VERSION "fleet-can-dataset generic_vehicle v0.1"

NS_ :

BS_:

BU_: ECM ABS APP BCM EPS

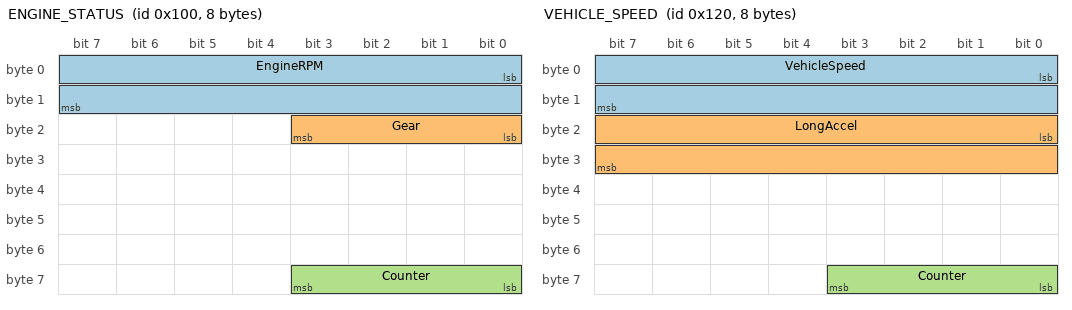
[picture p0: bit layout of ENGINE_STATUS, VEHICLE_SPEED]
BO_ 256 ENGINE_STATUS: 8 ECM
 SG_ EngineRPM : 0|16@1+ (0.25,0) [0|16383.75] "rpm" Vector__XXX
 SG_ Gear : 16|4@1+ (1,0) [0|15] "" Vector__XXX
 SG_ Counter : 56|4@1+ (1,0) [0|15] "" Vector__XXX

BO_ 288 VEHICLE_SPEED: 8 ABS
 SG_ VehicleSpeed : 0|16@1+ (0.01,0) [0|655.35] "km/h" Vector__XXX
 SG_ LongAccel : 16|16@1- (0.001,0) [-32.768|32.767] "m/s^2" Vector__XXX
 SG_ Counter : 56|4@1+ (1,0) [0|15] "" Vector__XXX

BO_ 336 ACCEL_PEDAL: 8 APP
 SG_ AccelPedalPos : 0|8@1+ (0.4,0) [0|100] "%" Vector__XXX
 SG_ Counter : 56|4@1+ (1,0) [0|15] "" Vector__XXX

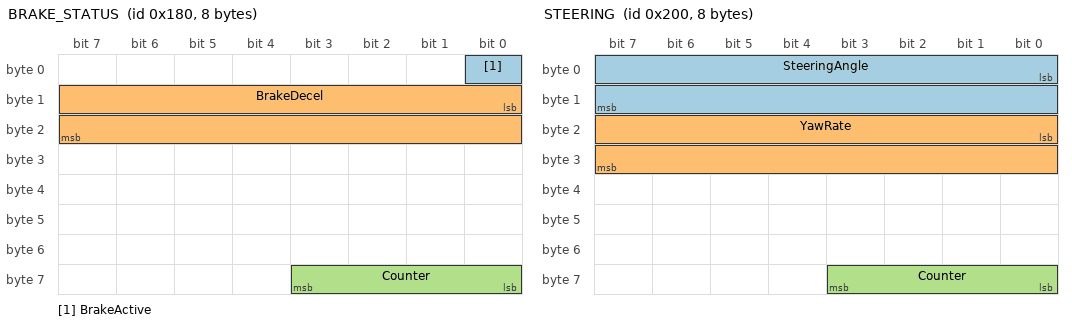
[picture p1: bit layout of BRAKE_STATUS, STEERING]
BO_ 384 BRAKE_STATUS: 8 BCM
 SG_ BrakeActive : 0|1@1+ (1,0) [0|1] "" Vector__XXX
 SG_ BrakeDecel : 8|16@1+ (0.001,0) [0|65.535] "m/s^2" Vector__XXX
 SG_ Counter : 56|4@1+ (1,0) [0|15] "" Vector__XXX

BO_ 512 STEERING: 8 EPS
 SG_ SteeringAngle : 0|16@1- (0.1,0) [-3276.8|3276.7] "deg" Vector__XXX
 SG_ YawRate : 16|16@1- (0.01,0) [-327.68|327.67] "deg/s" Vector__XXX
 SG_ Counter : 56|4@1+ (1,0) [0|15] "" Vector__XXX

CM_ "SYNTHETIC CAN MODEL. CAN IDs, layouts and scaling are defined by this project for research simulation. They are NOT taken from any real OEM vehicle.";
CM_ BO_ 256 "Synthetic engine status. RPM and gear derived from SUMO speed via a fixed gearbox model.";
CM_ BO_ 288 "Synthetic vehicle speed. Speed and longitudinal acceleration taken from SUMO via TraCI.";
CM_ BO_ 336 "Synthetic accelerator pedal position derived from positive SUMO acceleration.";
CM_ BO_ 384 "Synthetic brake status derived from negative SUMO acceleration.";
CM_ BO_ 512 "Synthetic steering angle and yaw rate derived from change in SUMO heading.";
CM_ SG_ 256 Counter "Rolling counter 0..15, incremented per transmitted frame of this message.";

BA_DEF_ BO_ "GenMsgCycleTime" INT 0 10000;
BA_DEF_DEF_ "GenMsgCycleTime" 100;
BA_ "GenMsgCycleTime" BO_ 256 10;
BA_ "GenMsgCycleTime" BO_ 288 20;
BA_ "GenMsgCycleTime" BO_ 336 20;
BA_ "GenMsgCycleTime" BO_ 384 20;
BA_ "GenMsgCycleTime" BO_ 512 10;
